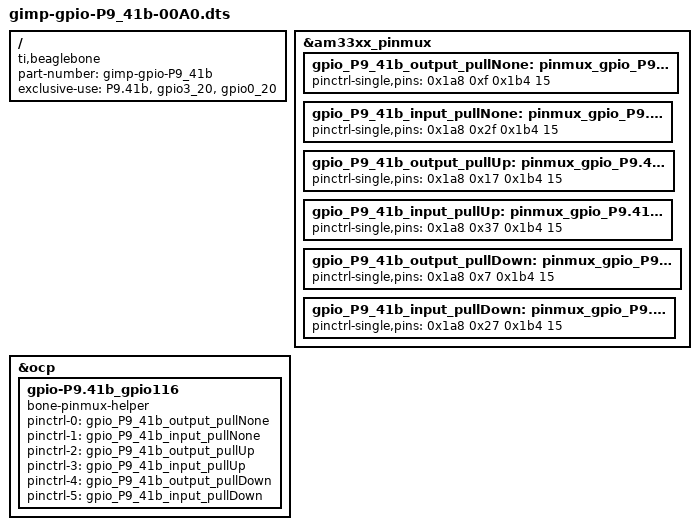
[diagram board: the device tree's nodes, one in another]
/*
* gimpbbio mux control of "P9.41b" ("gpio3_20", "gpio0_20")
*/
/dts-v1/;
/plugin/;

/ {
	compatible = "ti,beaglebone", "ti,beaglebone-black";

	/* identification */
	part-number = "gimp-gpio-P9_41b";
	/* version = "00A0"; */

	/* state the resources this cape uses */
	exclusive-use =
		/* the pin header uses */
		"P9.41b",

		/* the hardware IP uses */
		"gpio3_20", "gpio0_20";
	
	
	/* output_pullNone state */
	fragment@0 {
		target = <&am33xx_pinmux>;
		__overlay__ {
			gpio_P9_41b_output_pullNone: pinmux_gpio_P9.41b_output_pullNone {
				pinctrl-single,pins = <
					0x1a8 0xf	0x1b4 15
				>;
			};
		};
	};

	/* input_pullNone state */
	fragment@1 {
		target = <&am33xx_pinmux>;
		__overlay__ {
			gpio_P9_41b_input_pullNone: pinmux_gpio_P9.41b_input_pullNone {
				pinctrl-single,pins = <
					0x1a8 0x2f	0x1b4 15
				>;
			};
		};
	};

	/* output_pullUp state */
	fragment@2 {
		target = <&am33xx_pinmux>;
		__overlay__ {
			gpio_P9_41b_output_pullUp: pinmux_gpio_P9.41b_output_pullUp {
				pinctrl-single,pins = <
					0x1a8 0x17	0x1b4 15
				>;
			};
		};
	};

	/* input_pullUp state */
	fragment@3 {
		target = <&am33xx_pinmux>;
		__overlay__ {
			gpio_P9_41b_input_pullUp: pinmux_gpio_P9.41b_input_pullUp {
				pinctrl-single,pins = <
					0x1a8 0x37	0x1b4 15
				>;
			};
		};
	};

	/* output_pullDown state */
	fragment@4 {
		target = <&am33xx_pinmux>;
		__overlay__ {
			gpio_P9_41b_output_pullDown: pinmux_gpio_P9.41b_output_pullDown {
				pinctrl-single,pins = <
					0x1a8 0x7	0x1b4 15
				>;
			};
		};
	};

	/* input_pullDown state */
	fragment@5 {
		target = <&am33xx_pinmux>;
		__overlay__ {
			gpio_P9_41b_input_pullDown: pinmux_gpio_P9.41b_input_pullDown {
				pinctrl-single,pins = <
					0x1a8 0x27	0x1b4 15
				>;
			};
		};
	};

	fragment@6 {
		target = <&ocp>;
		__overlay__ {
			gpio-P9.41b_gpio116 {
				compatible = "bone-pinmux-helper";
				status = "okay";
				pinctrl-names = "output_pullNone", "input_pullNone", "output_pullUp", "input_pullUp", "output_pullDown", "input_pullDown";
				pinctrl-0 = <&gpio_P9_41b_output_pullNone>;
				pinctrl-1 = <&gpio_P9_41b_input_pullNone>;
				pinctrl-2 = <&gpio_P9_41b_output_pullUp>;
				pinctrl-3 = <&gpio_P9_41b_input_pullUp>;
				pinctrl-4 = <&gpio_P9_41b_output_pullDown>;
				pinctrl-5 = <&gpio_P9_41b_input_pullDown>;
			};
		};
	};

};
